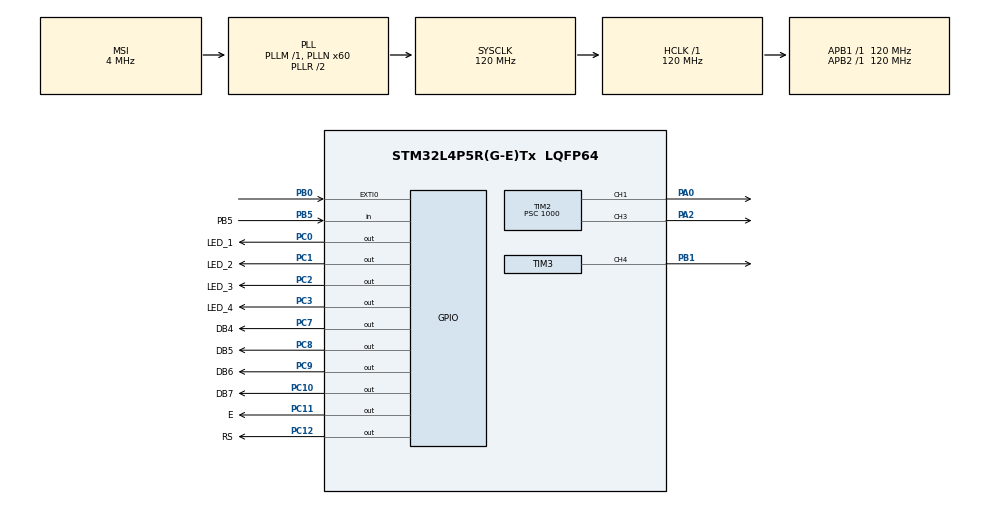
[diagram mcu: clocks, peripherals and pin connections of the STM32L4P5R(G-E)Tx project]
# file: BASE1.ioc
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Mcu.Family=STM32L4
Mcu.Name=STM32L4P5R(G-E)Tx
Mcu.Package=LQFP64
NVIC.PriorityGroup=NVIC_PRIORITYGROUP_4
NVIC.TIM2_IRQn=true\:0\:0\:false\:false\:true\:true\:true\:true
PA0.Signal=S_TIM2_CH1
PA1.Signal=ADCx_IN6
PA13\ (JTMS/SWDIO).Mode=JTAG_5_pins
PA13\ (JTMS/SWDIO).Signal=SYS_JTMS-SWDIO
PA14\ (JTCK/SWCLK).Mode=JTAG_5_pins
PA14\ (JTCK/SWCLK).Signal=SYS_JTCK-SWCLK
PA15\ (JTDI).Mode=JTAG_5_pins
PA15\ (JTDI).Signal=SYS_JTDI
PA2.Signal=S_TIM2_CH3
PB0.GPIO_ModeDefaultEXTI=GPIO_MODE_IT_FALLING
PB0.Signal=GPXTI0
PB1.Signal=S_TIM3_CH4
PB3\ (JTDO/TRACESWO).Mode=JTAG_5_pins
PB3\ (JTDO/TRACESWO).Signal=SYS_JTDO-SWO
PB4\ (NJTRST).Mode=JTAG_5_pins
PB4\ (NJTRST).Signal=SYS_JTRST
PB5.GPIO_Label=PB5
PB5.Signal=GPIO_Input
PC0.GPIO_Label=LED_1
PC0.Signal=GPIO_Output
PC1.GPIO_Label=LED_2
PC1.Signal=GPIO_Output
PC10.GPIO_Label=DB7
PC10.Signal=GPIO_Output
PC11.GPIO_Label=E
PC11.Signal=GPIO_Output
PC12.GPIO_Label=RS
PC12.Signal=GPIO_Output
PC2.GPIO_Label=LED_3
PC2.Signal=GPIO_Output
PC3.GPIO_Label=LED_4
PC3.Signal=GPIO_Output
PC7.GPIO_Label=DB4
PC7.Signal=GPIO_Output
PC8.GPIO_Label=DB5
PC8.Signal=GPIO_Output
PC9.GPIO_Label=DB6
PC9.Signal=GPIO_Output
PH0-OSC_IN\ (PH0).Mode=HSE-External-Oscillator
PH0-OSC_IN\ (PH0).Signal=RCC_OSC_IN
PH1-OSC_OUT\ (PH1).Mode=HSE-External-Oscillator
PH1-OSC_OUT\ (PH1).Signal=RCC_OSC_OUT
ProjectManager.HeapSize=0x200
ProjectManager.StackSize=0x400
ProjectManager.TargetToolchain=STM32CubeIDE
RCC.ADCFreq_Value=32000000
RCC.AHBFreq_Value=120000000
RCC.APB1Freq_Value=120000000
RCC.APB1TimFreq_Value=120000000
RCC.APB2Freq_Value=120000000
RCC.APB2TimFreq_Value=120000000
RCC.CortexFreq_Value=120000000
RCC.HCLKFreq_Value=120000000
RCC.HSE_VALUE=8000000
RCC.HSI48_VALUE=48000000
RCC.HSI_VALUE=16000000
RCC.MSI_VALUE=4000000
RCC.PLLN=60
RCC.PLLSAI1N=16
RCC.SYSCLKFreq_VALUE=120000000
RCC.SYSCLKSource=RCC_SYSCLKSOURCE_PLLCLK
RCC.USBFreq_Value=32000000
RCC.VCOOutputFreq_Value=240000000
SH.ADCx_IN6.0=ADC1_IN6
SH.S_TIM2_CH1.0=TIM2_CH1,PWM Generation1 CH1
SH.S_TIM2_CH3.0=TIM2_CH3,PWM Generation3 CH3
SH.S_TIM3_CH4.0=TIM3_CH4,PWM Generation4 CH4
TIM2.AutoReloadPreload=TIM_AUTORELOAD_PRELOAD_ENABLE
TIM2.Channel-PWM\ Generation1\ CH1=TIM_CHANNEL_1
TIM2.Channel-PWM\ Generation2\ No\ Output=TIM_CHANNEL_2
TIM2.Channel-PWM\ Generation3\ CH3=TIM_CHANNEL_3
TIM2.Channel-PWM\ Generation4\ No\ Output=TIM_CHANNEL_4
TIM2.Period=135
TIM2.Prescaler=1000
TIM2.Pulse-PWM\ Generation1\ CH1=50
TIM2.Pulse-PWM\ Generation3\ CH3=50
TIM2.Pulse-PWM\ Generation4\ No\ Output=50
TIM2.TIM_MasterOutputTrigger=TIM_TRGO_ENABLE
TIM2.TIM_MasterSlaveMode=TIM_MASTERSLAVEMODE_ENABLE
TIM3.AutoReloadPreload=TIM_AUTORELOAD_PRELOAD_ENABLE
TIM3.Channel-PWM\ Generation4\ CH4=TIM_CHANNEL_4
TIM3.Period=12-1
TIM3.Prescaler=257-1
TIM3.Pulse-PWM\ Generation4\ CH4=4
TIM3.TIM_MasterOutputTrigger=TIM_TRGO_RESET
TIM3.TIM_MasterSlaveMode=TIM_MASTERSLAVEMODE_DISABLE
VP_TIM2_VS_ClockSourceINT.Mode=Internal
VP_TIM2_VS_no_output4.Mode=PWM Generation4 No Output
VP_TIM3_VS_ClockSourceINT.Mode=Internal
VP_TIM3_VS_ClockSourceITR.Mode=TriggerSource_ITR1
board=custom

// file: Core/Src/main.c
/* USER CODE BEGIN Header */
/**
  ******************************************************************************
  * @file           : main.c
  * @brief          : Main program body
  ******************************************************************************
  * @attention
  *
  * <h2><center>&copy; Copyright (c) 2022 STMicroelectronics.
  * All rights reserved.</center></h2>
  *
  * This software component is licensed by ST under BSD 3-Clause license,
  * the "License"; You may not use this file except in compliance with the
  * License. You may obtain a copy of the License at:
  *                        opensource.org/licenses/BSD-3-Clause
  *
  ******************************************************************************
  */
/* USER CODE END Header */
#include "main.h"

/* USER CODE BEGIN Includes */
//#include "IR_Code.c"
/* USER CODE END Includes */

/* USER CODE BEGIN PTD */
uint32_t tim2;
uint32_t tim3;
/* USER CODE END PTD */

TIM_HandleTypeDef htim2;
TIM_HandleTypeDef htim3;

/* USER CODE BEGIN PV */
uint8_t car_passed = 0;
uint16_t battery_charge;

//car_passed variable states
//car_passed = 0 - Lap timer has been turned ON and it's waiting for first pass
//car_passed = 1 - First pass occurred, start timing first lap.
//car_passed = 2 - Lap is being timed, changes to car_passed = 3 after one second of delay in order not to get false positive sensor readings.
//car_passed = 3 - Lap is being timed.
//car_passed = 4 - Car has completed a lap, reset timer, show time and go back to car_passed = 1

uint8_t show_time  = 0;
uint8_t update_lcd = 0;
/* USER CODE END PV */

void SystemClock_Config(void);
static void MX_GPIO_Init(void);
static void MX_TIM3_Init(void);
static void MX_TIM2_Init(void);
/* USER CODE BEGIN PFP */

/*
void delay_us(uint16_t us)
{
	__HAL_TIM_SET_COUNTER(&htim1,0);  // set the counter value a 0
	while (__HAL_TIM_GET_COUNTER(&htim1) < us);  // wait for the counter to reach the us input in the parameter
}
*/

/* USER CODE END PFP */

int main(void)
{

  /* MCU Configuration--------------------------------------------------------*/

  /* Reset of all peripherals, Initializes the Flash interface and the Systick. */
  HAL_Init();

  /* Configure the system clock */
  SystemClock_Config();

  /* Initialize all configured peripherals */
  MX_GPIO_Init();
  MX_TIM3_Init();
  MX_TIM2_Init();
  /* USER CODE BEGIN 2 */

  //LED_1 - ON: Timer is running OFF: it's not
  //LED_2 - IR detected.
  //LED_3 -
  //LED_4 -

  //Turn Off Leds
  HAL_GPIO_WritePin(GPIOC, LED_1_Pin, 1);
  HAL_GPIO_WritePin(GPIOC, LED_2_Pin, 1);
  HAL_GPIO_WritePin(GPIOC, LED_3_Pin, 1);
  HAL_GPIO_WritePin(GPIOC, LED_4_Pin, 0);
  //Turn on IR leds.
  //HAL_TIM_Base_Start(&htim2);

  HAL_TIM_PWM_Start(&htim3, TIM_CHANNEL_4);

  /* USER CODE END 2 */

  /* Infinite loop */
  while (1)
  {

    /* USER CODE BEGIN 3 */

	  /*Master timer time table:
	   * Prescaler = 1000
	   * Period = 190 - 200Hz
	   * Period = 125 - 300Hz
	   * Period = 94 - 400Hz
	   */

  }
  /* USER CODE END 3 */
}

void SystemClock_Config(void)
{
  RCC_OscInitTypeDef RCC_OscInitStruct = {0};
  RCC_ClkInitTypeDef RCC_ClkInitStruct = {0};

  /** Configure the main internal regulator output voltage
  */
  if (HAL_PWREx_ControlVoltageScaling(PWR_REGULATOR_VOLTAGE_SCALE1_BOOST) != HAL_OK)
  {
    Error_Handler();
  }

  /** Initializes the RCC Oscillators according to the specified parameters
  * in the RCC_OscInitTypeDef structure.
  */
  RCC_OscInitStruct.OscillatorType = RCC_OSCILLATORTYPE_MSI;
  RCC_OscInitStruct.MSIState = RCC_MSI_ON;
  RCC_OscInitStruct.MSICalibrationValue = 0;
  RCC_OscInitStruct.MSIClockRange = RCC_MSIRANGE_6;
  RCC_OscInitStruct.PLL.PLLState = RCC_PLL_ON;
  RCC_OscInitStruct.PLL.PLLSource = RCC_PLLSOURCE_MSI;
  RCC_OscInitStruct.PLL.PLLM = 1;
  RCC_OscInitStruct.PLL.PLLN = 60;
  RCC_OscInitStruct.PLL.PLLP = RCC_PLLP_DIV2;
  RCC_OscInitStruct.PLL.PLLQ = RCC_PLLQ_DIV2;
  RCC_OscInitStruct.PLL.PLLR = RCC_PLLR_DIV2;
  if (HAL_RCC_OscConfig(&RCC_OscInitStruct) != HAL_OK)
  {
    Error_Handler();
  }

  /** Initializes the CPU, AHB and APB buses clocks
  */
  RCC_ClkInitStruct.ClockType = RCC_CLOCKTYPE_HCLK|RCC_CLOCKTYPE_SYSCLK
                              |RCC_CLOCKTYPE_PCLK1|RCC_CLOCKTYPE_PCLK2;
  RCC_ClkInitStruct.SYSCLKSource = RCC_SYSCLKSOURCE_PLLCLK;
  RCC_ClkInitStruct.AHBCLKDivider = RCC_SYSCLK_DIV1;
  RCC_ClkInitStruct.APB1CLKDivider = RCC_HCLK_DIV1;
  RCC_ClkInitStruct.APB2CLKDivider = RCC_HCLK_DIV1;

  if (HAL_RCC_ClockConfig(&RCC_ClkInitStruct, FLASH_LATENCY_5) != HAL_OK)
  {
    Error_Handler();
  }
}

static void MX_TIM2_Init(void)
{

  TIM_ClockConfigTypeDef sClockSourceConfig = {0};
  TIM_MasterConfigTypeDef sMasterConfig = {0};
  TIM_OC_InitTypeDef sConfigOC = {0};

  htim2.Instance = TIM2;
  htim2.Init.Prescaler = 1000;
  htim2.Init.CounterMode = TIM_COUNTERMODE_UP;
  htim2.Init.Period = 135;
  htim2.Init.ClockDivision = TIM_CLOCKDIVISION_DIV1;
  htim2.Init.AutoReloadPreload = TIM_AUTORELOAD_PRELOAD_ENABLE;
  if (HAL_TIM_Base_Init(&htim2) != HAL_OK)
  {
    Error_Handler();
  }
  sClockSourceConfig.ClockSource = TIM_CLOCKSOURCE_INTERNAL;
  if (HAL_TIM_ConfigClockSource(&htim2, &sClockSourceConfig) != HAL_OK)
  {
    Error_Handler();
  }
  if (HAL_TIM_PWM_Init(&htim2) != HAL_OK)
  {
    Error_Handler();
  }
  sMasterConfig.MasterOutputTrigger = TIM_TRGO_ENABLE;
  sMasterConfig.MasterSlaveMode = TIM_MASTERSLAVEMODE_ENABLE;
  if (HAL_TIMEx_MasterConfigSynchronization(&htim2, &sMasterConfig) != HAL_OK)
  {
    Error_Handler();
  }
  sConfigOC.OCMode = TIM_OCMODE_PWM1;
  sConfigOC.Pulse = 50;
  sConfigOC.OCPolarity = TIM_OCPOLARITY_HIGH;
  sConfigOC.OCFastMode = TIM_OCFAST_DISABLE;
  if (HAL_TIM_PWM_ConfigChannel(&htim2, &sConfigOC, TIM_CHANNEL_1) != HAL_OK)
  {
    Error_Handler();
  }
  if (HAL_TIM_PWM_ConfigChannel(&htim2, &sConfigOC, TIM_CHANNEL_3) != HAL_OK)
  {
    Error_Handler();
  }
  if (HAL_TIM_PWM_ConfigChannel(&htim2, &sConfigOC, TIM_CHANNEL_4) != HAL_OK)
  {
    Error_Handler();
  }
  HAL_TIM_MspPostInit(&htim2);

}

static void MX_TIM3_Init(void)
{

  TIM_ClockConfigTypeDef sClockSourceConfig = {0};
  TIM_SlaveConfigTypeDef sSlaveConfig = {0};
  TIM_MasterConfigTypeDef sMasterConfig = {0};
  TIM_OC_InitTypeDef sConfigOC = {0};

  htim3.Instance = TIM3;
  htim3.Init.Prescaler = 257-1;
  htim3.Init.CounterMode = TIM_COUNTERMODE_UP;
  htim3.Init.Period = 12-1;
  htim3.Init.ClockDivision = TIM_CLOCKDIVISION_DIV1;
  htim3.Init.AutoReloadPreload = TIM_AUTORELOAD_PRELOAD_ENABLE;
  if (HAL_TIM_Base_Init(&htim3) != HAL_OK)
  {
    Error_Handler();
  }
  sClockSourceConfig.ClockSource = TIM_CLOCKSOURCE_INTERNAL;
  if (HAL_TIM_ConfigClockSource(&htim3, &sClockSourceConfig) != HAL_OK)
  {
    Error_Handler();
  }
  if (HAL_TIM_PWM_Init(&htim3) != HAL_OK)
  {
    Error_Handler();
  }
  sSlaveConfig.SlaveMode = TIM_SLAVEMODE_DISABLE;
  sSlaveConfig.InputTrigger = TIM_TS_ITR1;
  if (HAL_TIM_SlaveConfigSynchro(&htim3, &sSlaveConfig) != HAL_OK)
  {
    Error_Handler();
  }
  sMasterConfig.MasterOutputTrigger = TIM_TRGO_RESET;
  sMasterConfig.MasterSlaveMode = TIM_MASTERSLAVEMODE_DISABLE;
  if (HAL_TIMEx_MasterConfigSynchronization(&htim3, &sMasterConfig) != HAL_OK)
  {
    Error_Handler();
  }
  sConfigOC.OCMode = TIM_OCMODE_PWM1;
  sConfigOC.Pulse = 4;
  sConfigOC.OCPolarity = TIM_OCPOLARITY_HIGH;
  sConfigOC.OCFastMode = TIM_OCFAST_DISABLE;
  if (HAL_TIM_PWM_ConfigChannel(&htim3, &sConfigOC, TIM_CHANNEL_4) != HAL_OK)
  {
    Error_Handler();
  }
  HAL_TIM_MspPostInit(&htim3);

}

static void MX_GPIO_Init(void)
{
  GPIO_InitTypeDef GPIO_InitStruct = {0};

  /* GPIO Ports Clock Enable */
  __HAL_RCC_GPIOH_CLK_ENABLE();
  __HAL_RCC_GPIOC_CLK_ENABLE();
  __HAL_RCC_GPIOA_CLK_ENABLE();
  __HAL_RCC_GPIOB_CLK_ENABLE();

  /*Configure GPIO pin Output Level */
  HAL_GPIO_WritePin(GPIOC, LED_1_Pin|LED_2_Pin|LED_3_Pin|LED_4_Pin
                          |DB4_Pin|DB5_Pin|DB6_Pin|DB7_Pin
                          |E_Pin|RS_Pin, GPIO_PIN_RESET);

  /*Configure GPIO pins : LED_1_Pin LED_2_Pin LED_3_Pin LED_4_Pin
                           DB4_Pin DB5_Pin DB6_Pin DB7_Pin
                           E_Pin RS_Pin */
  GPIO_InitStruct.Pin = LED_1_Pin|LED_2_Pin|LED_3_Pin|LED_4_Pin
                          |DB4_Pin|DB5_Pin|DB6_Pin|DB7_Pin
                          |E_Pin|RS_Pin;
  GPIO_InitStruct.Mode = GPIO_MODE_OUTPUT_PP;
  GPIO_InitStruct.Pull = GPIO_NOPULL;
  GPIO_InitStruct.Speed = GPIO_SPEED_FREQ_LOW;
  HAL_GPIO_Init(GPIOC, &GPIO_InitStruct);

  /*Configure GPIO pin : PA1 */
  GPIO_InitStruct.Pin = GPIO_PIN_1;
  GPIO_InitStruct.Mode = GPIO_MODE_ANALOG_ADC_CONTROL;
  GPIO_InitStruct.Pull = GPIO_NOPULL;
  HAL_GPIO_Init(GPIOA, &GPIO_InitStruct);

  /*Configure GPIO pin : PB0 */
  GPIO_InitStruct.Pin = GPIO_PIN_0;
  GPIO_InitStruct.Mode = GPIO_MODE_IT_FALLING;
  GPIO_InitStruct.Pull = GPIO_NOPULL;
  HAL_GPIO_Init(GPIOB, &GPIO_InitStruct);

  /*Configure GPIO pin : PB5_Pin */
  GPIO_InitStruct.Pin = PB5_Pin;
  GPIO_InitStruct.Mode = GPIO_MODE_INPUT;
  GPIO_InitStruct.Pull = GPIO_NOPULL;
  HAL_GPIO_Init(PB5_GPIO_Port, &GPIO_InitStruct);

}

void Error_Handler(void)
{
  __disable_irq();
  while (1)
  {
  }
}
